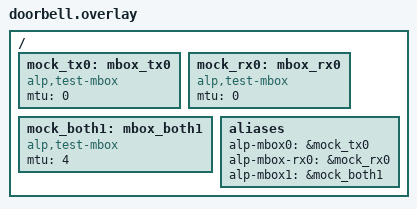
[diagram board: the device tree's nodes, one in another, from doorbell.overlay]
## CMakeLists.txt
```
# SPDX-License-Identifier: Apache-2.0

cmake_minimum_required(VERSION 3.20)

find_package(Zephyr REQUIRED HINTS $ENV{ZEPHYR_BASE})
project(alp_sdk_mproc_test LANGUAGES C)

target_sources(app PRIVATE src/main.c)

# alp_sdk.mproc.doorbell: mock MBOX controllers (src/mbox_mock.c).
if(ALP_MPROC_TEST_DOORBELL)
  target_sources(app PRIVATE src/mbox_mock.c)
  target_compile_definitions(app PRIVATE ALP_MPROC_TEST_DOORBELL)
endif()
```

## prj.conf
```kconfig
# SPDX-License-Identifier: Apache-2.0

CONFIG_ZTEST=y
CONFIG_ALP_SDK=y
CONFIG_LOG=y
CONFIG_PRINTK=y
CONFIG_THREAD_LOCAL_STORAGE=y
CONFIG_MAIN_STACK_SIZE=4096
```

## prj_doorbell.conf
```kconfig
# SPDX-License-Identifier: Apache-2.0
CONFIG_MBOX=y
CONFIG_ALP_SDK_MPROC=y
```

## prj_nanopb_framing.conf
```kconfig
# SPDX-License-Identifier: Apache-2.0
# Twister overlay: flips on CONFIG_ALP_SDK_MPROC_NANOPB_FRAMING so the
# alp_mbox_send / mbox_rx_cb framing code path in mproc_zephyr.c is
# compile-verified.  Real mbox roundtrip remains parked behind HIL
# (no mbox device exists under native_sim); the same encode/decode
# ZTESTs in src/main.c cover the framing helper directly.

CONFIG_MBOX=y
CONFIG_ALP_SDK_MPROC=y
CONFIG_ALP_SDK_MPROC_NANOPB_FRAMING=y
CONFIG_ALP_SDK_MPROC_FRAME_MAX_BYTES=256
```

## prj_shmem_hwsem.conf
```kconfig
# SPDX-License-Identifier: Apache-2.0
#
# Extra config for the alp_sdk.mproc.shmem_hwsem scenario: turn the
# real MPROC backend on so alp_shmem_* + alp_hwsem_* dispatch
# through the DT-alias-lookup + k_sem paths (rather than the
# NOSUPPORT shortcircuit).
#
# CONFIG_MBOX=y is required because CONFIG_ALP_SDK_MPROC has
# `depends on MBOX` in zephyr/Kconfig -- without it the Kconfig
# solver silently demotes the assignment to 'n' and the wrapper
# keeps shortcircuiting to ALP_ERR_NOSUPPORT.

CONFIG_MBOX=y
CONFIG_ALP_SDK_MPROC=y
```

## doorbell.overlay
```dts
/*
 * SPDX-License-Identifier: Apache-2.0
 *
 * alp_sdk.mproc.doorbell: mock mbox pairs (alp-shmem0 comes from
 * native_sim_native_64.overlay; src/mbox_mock.c maps its 0x70000000).
 *   channel 0: tx mtu 0 (doorbell-only) + separate rx device (alp-mbox-rx0)
 *   channel 1: one device, mtu 4, no alp-mbox-rx1 (RX falls back to TX)
 */
/ {
	mock_tx0: mbox_tx0 {
		compatible = "alp,test-mbox";
		#mbox-cells = <1>;
		mtu = <0>;
		status = "okay";
	};
	mock_rx0: mbox_rx0 {
		compatible = "alp,test-mbox";
		#mbox-cells = <1>;
		mtu = <0>;
		status = "okay";
	};
	mock_both1: mbox_both1 {
		compatible = "alp,test-mbox";
		#mbox-cells = <1>;
		mtu = <4>;
		status = "okay";
	};

	aliases {
		alp-mbox0    = &mock_tx0;
		alp-mbox-rx0 = &mock_rx0;
		alp-mbox1    = &mock_both1;
	};
};
```

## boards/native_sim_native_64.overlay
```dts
/*
 * Copyright 2026 Alp Lab AB
 * SPDX-License-Identifier: Apache-2.0
 *
 * DT overlay for the alp_sdk.mproc.shmem_hwsem ZTEST scenario.
 * Declares two alp-shmem aliases backed by mmio-sram nodes with
 * arbitrary "addresses" -- native_sim never dereferences them; the
 * tests only verify the wrapper reports the DT-anchored base+size
 * verbatim.  Real-silicon boards define the same aliases against
 * actual reserved-memory carve-outs (orchestrator-allocated).
 */

/ {
    alp_shmem0_node: shmem@70000000 {
        compatible = "mmio-sram";
        reg = <0x70000000 0x1000>;
        status = "okay";
    };

    alp_shmem1_node: shmem@70001000 {
        compatible = "mmio-sram";
        reg = <0x70001000 0x800>;
        status = "okay";
    };

    aliases {
        alp-shmem0 = &alp_shmem0_node;
        alp-shmem1 = &alp_shmem1_node;
    };
};
```

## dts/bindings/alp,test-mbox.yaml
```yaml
# SPDX-License-Identifier: Apache-2.0
description: Test-only mbox mock for tests/zephyr/mproc (src/mbox_mock.c).
compatible: "alp,test-mbox"
include: [base.yaml, mailbox-controller.yaml]
properties:
  mtu:
    type: int
    default: 0
    description: Value mbox_mtu_get() reports; 0 mimics a doorbell-only controller.
```

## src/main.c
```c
/*
 * Copyright 2026 Alp Lab AB
 * SPDX-License-Identifier: Apache-2.0
 *
 * Smoke tests for <alp/mproc.h> under native_sim, covering four
 * buckets driven by the testcase.yaml scenarios:
 *
 *   1. NOSUPPORT-fallback (default scenario, CONFIG_ALP_SDK_MPROC=n).
 *      Guarded with #if !defined(CONFIG_ALP_SDK_MPROC).  Verifies
 *      alp_shmem_open / alp_mbox_open / alp_hwsem_open all return
 *      NULL with ALP_ERR_NOSUPPORT plus every NULL-arg branch
 *      stays safe.
 *
 *   2. shmem-impl (alp_sdk.mproc.shmem_hwsem scenario,
 *      CONFIG_ALP_SDK_MPROC=y + boards/native_sim_native_64.overlay
 *      declaring alp-shmem0 + alp-shmem1).  Guarded with
 *      #if defined(CONFIG_ALP_SDK_MPROC) && DT_NODE_HAS_STATUS(DT_ALIAS(alp_shmem0), okay).
 *      Verifies the DT-alias lookup table resolves names to the
 *      right base+size, unknown names hit NOT_READY, the handle
 *      pool exhausts cleanly.
 *
 *   3. hwsem-impl (same scenario as shmem-impl).  Verifies the
 *      k_sem-backed lock/unlock cycle, contention between distinct
 *      handles on the same id, timed lock semantics, out-of-range
 *      id rejection, and the "unlock without lock returns INVAL"
 *      contract.
 *
 *   4. IPC envelope framing (always on -- no MPROC backend needed).
 *      Exercises alp_mproc_frame_encode / alp_mproc_frame_decode
 *      directly so the interim placeholder codec stays correct
 *      ahead of the (deferred, no committed version) nanopb-generated
 *      wire format.  The
 *      alp_sdk.mproc.nanopb_framing scenario additionally compiles
 *      CONFIG_ALP_SDK_MPROC_NANOPB_FRAMING=y so the framing branch
 *      in alp_mbox_send / mbox_rx_cb builds cleanly.
 */

#include <string.h>

#include <zephyr/devicetree.h>
#include <zephyr/ztest.h>

#include "alp/peripheral.h"
#include "alp/mproc.h"
#include "proto/alp_mproc_frame.h"

ZTEST_SUITE(alp_mproc, NULL, NULL, NULL, NULL, NULL);

/* The "no backend" assertions below presume CONFIG_ALP_SDK_MPROC=n
 * so the wrapper shortcircuits to NOSUPPORT.  When MPROC is on (used
 * by the framing scenario below) the wrapper validates args and
 * walks the DT-alias lookup, which yields NOT_READY under native_sim
 * because no `alp-mbox0` / `alp_shmem0` aliases exist there.  Both
 * states are "no backend" -- the framing scenario covers the
 * framing path itself, not these no-backend assertions, so skipping
 * them under MPROC=y keeps each scenario laser-focused. */
#if !defined(CONFIG_ALP_SDK_MPROC)

ZTEST(alp_mproc, test_shmem_open_no_backend_returns_null)
{
	alp_shmem_config_t cfg = { .name = "alp_shmem0", .size = 4096 };
	alp_shmem_t       *s   = alp_shmem_open(&cfg);
	zassert_is_null(s);
	zassert_equal(alp_last_error(), ALP_ERR_NOSUPPORT);
}

ZTEST(alp_mproc, test_shmem_open_null_invalid)
{
	zassert_is_null(alp_shmem_open(NULL));
	zassert_equal(alp_last_error(), ALP_ERR_INVAL);
}

ZTEST(alp_mproc, test_shmem_view_null_handle_errors)
{
	void  *base = (void *)0xDEADBEEF;
	size_t size = 999;
	zassert_equal(alp_shmem_view(NULL, &base, &size), ALP_ERR_NOT_READY);
	zassert_is_null(base);
	zassert_equal(size, 0);
	alp_shmem_close(NULL);
}

#ifndef ALP_MPROC_TEST_DOORBELL /* the doorbell scenario defines alp-mbox0 */
ZTEST(alp_mproc, test_mbox_open_no_backend_returns_null)
{
	alp_mbox_config_t cfg = { .channel = 0, .peer = ALP_CORE_M55_HE };
	alp_mbox_t       *m   = alp_mbox_open(&cfg);
	zassert_is_null(m);
	zassert_equal(alp_last_error(), ALP_ERR_NOSUPPORT);
}
#endif

ZTEST(alp_mproc, test_mbox_lifecycle_null_handle_safe)
{
	uint8_t buf[4] = { 0 };
	zassert_equal(alp_mbox_send(NULL, buf, sizeof(buf), 100), ALP_ERR_NOT_READY);
	zassert_equal(alp_mbox_set_callback(NULL, NULL, NULL), ALP_ERR_NOT_READY);
	alp_mbox_close(NULL);
}

ZTEST(alp_mproc, test_hwsem_open_no_backend_returns_null)
{
	alp_hwsem_t *s = alp_hwsem_open(0);
	zassert_is_null(s);
	zassert_equal(alp_last_error(), ALP_ERR_NOSUPPORT);
}

ZTEST(alp_mproc, test_hwsem_lifecycle_null_handle_safe)
{
	zassert_equal(alp_hwsem_try_lock(NULL), ALP_ERR_NOT_READY);
	zassert_equal(alp_hwsem_lock(NULL, 100), ALP_ERR_NOT_READY);
	zassert_equal(alp_hwsem_unlock(NULL), ALP_ERR_NOT_READY);
	alp_hwsem_close(NULL);
}

#endif /* !CONFIG_ALP_SDK_MPROC */

/* ------------------------------------------------------------------ */
/* IPC envelope (src/common/proto/alp_mproc_frame.{h,c}) — interim,   */
/* deferred (no committed version for the real nanopb wire)           */
/*                                                                     */
/* Placeholder binary framing exercised here directly because no real  */
/* mbox peer is available under native_sim.  When the eventual         */
/* nanopb codec drops in, these tests get rewritten against the        */
/* generated pb_encode / pb_decode entry points and verify the same    */
/* round-trip contract.                                                */
/* ------------------------------------------------------------------ */

ZTEST(alp_mproc, test_frame_encode_decode_roundtrip)
{
	const uint8_t payload[] = { 0xDE, 0xAD, 0xBE, 0xEF };
	uint8_t       framed[64];
	size_t        framed_len = 0;
	zassert_equal(
	    alp_mproc_frame_encode(42, payload, sizeof(payload), framed, sizeof(framed), &framed_len),
	    ALP_OK);
	zassert_equal(framed_len, ALP_MPROC_FRAME_HEADER_BYTES + sizeof(payload));

	uint32_t       seq         = 0;
	const uint8_t *payload_out = NULL;
	size_t         payload_len = 0;
	zassert_equal(alp_mproc_frame_decode(framed, framed_len, &seq, &payload_out, &payload_len),
	              ALP_OK);
	zassert_equal(seq, 42u);
	zassert_equal(payload_len, sizeof(payload));
	zassert_not_null(payload_out);
	zassert_equal(memcmp(payload_out, payload, sizeof(payload)),
	              0,
	              "payload bytes must round-trip unchanged");
}

ZTEST(alp_mproc, test_frame_encode_zero_payload_succeeds)
{
	uint8_t framed[ALP_MPROC_FRAME_HEADER_BYTES];
	size_t  framed_len = 0;
	zassert_equal(alp_mproc_frame_encode(1, NULL, 0, framed, sizeof(framed), &framed_len), ALP_OK);
	zassert_equal(framed_len, ALP_MPROC_FRAME_HEADER_BYTES);
}

ZTEST(alp_mproc, test_frame_encode_null_out_invalid)
{
	size_t framed_len = 99;
	zassert_equal(alp_mproc_frame_encode(1, "abc", 3, NULL, 999, &framed_len), ALP_ERR_INVAL);
	zassert_equal(framed_len, 0u, "out_len must be zeroed on failure");
}

ZTEST(alp_mproc, test_frame_encode_payload_null_with_nonzero_len)
{
	uint8_t framed[32];
	zassert_equal(alp_mproc_frame_encode(1, NULL, 4, framed, sizeof(framed), NULL), ALP_ERR_INVAL);
}

ZTEST(alp_mproc, test_frame_encode_capacity_short)
{
	const uint8_t payload[] = { 1, 2, 3, 4, 5, 6, 7, 8 };
	uint8_t       framed[ALP_MPROC_FRAME_HEADER_BYTES + 4]; /* too small for the 8-byte payload */
	zassert_equal(alp_mproc_frame_encode(1, payload, sizeof(payload), framed, sizeof(framed), NULL),
	              ALP_ERR_NOMEM);
}

ZTEST(alp_mproc, test_frame_decode_short_frame_errors)
{
	uint8_t frame[ALP_MPROC_FRAME_HEADER_BYTES - 1] = { 0 };
	zassert_equal(alp_mproc_frame_decode(frame, sizeof(frame), NULL, NULL, NULL), ALP_ERR_IO);
}

ZTEST(alp_mproc, test_frame_decode_bad_magic_errors)
{
	/* Encode a valid frame, then corrupt the magic. */
	const uint8_t payload[] = { 0xAB };
	uint8_t       framed[32];
	size_t        framed_len = 0;
	zassert_equal(
	    alp_mproc_frame_encode(1, payload, sizeof(payload), framed, sizeof(framed), &framed_len),
	    ALP_OK);
	framed[0] ^= 0xFFu;
	zassert_equal(alp_mproc_frame_decode(framed, framed_len, NULL, NULL, NULL), ALP_ERR_IO);
}

ZTEST(alp_mproc, test_frame_decode_declared_len_overflow_errors)
{
	/* Header claims a payload longer than the frame -- a peer-side
     * bug or a truncated transfer.  Receiver must drop. */
	uint8_t framed[ALP_MPROC_FRAME_HEADER_BYTES + 4];
	/* Magic */
	framed[0] = 0x41;
	framed[1] = 0x4D;
	framed[2] = 0x50;
	framed[3] = 0x46;
	/* Sequence */
	framed[4] = 1;
	framed[5] = 0;
	framed[6] = 0;
	framed[7] = 0;
	/* Declared length = 100, actual payload only 4 bytes */
	framed[8]  = 100;
	framed[9]  = 0;
	framed[10] = 0;
	framed[11] = 0;
	framed[12] = 0xDE;
	framed[13] = 0xAD;
	framed[14] = 0xBE;
	framed[15] = 0xEF;
	zassert_equal(alp_mproc_frame_decode(framed, sizeof(framed), NULL, NULL, NULL), ALP_ERR_IO);
}

ZTEST(alp_mproc, test_frame_decode_null_frame_invalid)
{
	uint32_t       seq         = 99;
	const uint8_t *payload_out = (const uint8_t *)0xDEADBEEF;
	size_t         payload_len = 99;
	zassert_equal(alp_mproc_frame_decode(NULL, 0, &seq, &payload_out, &payload_len), ALP_ERR_INVAL);
	zassert_equal(seq, 0u, "seq must be zeroed on failure");
	zassert_is_null(payload_out, "payload_out must be NULLed on failure");
	zassert_equal(payload_len, 0u, "payload_len must be zeroed on failure");
}

/* ------------------------------------------------------------------ */
/* Real backend (CONFIG_ALP_SDK_MPROC=y + DT overlay supplying        */
/* alp-shmem0..1 + the k_sem-backed hwsem fallback).                  */
/* ------------------------------------------------------------------ */
#if defined(CONFIG_ALP_SDK_MPROC) && DT_NODE_HAS_STATUS(DT_ALIAS(alp_shmem0), okay)

ZTEST(alp_mproc, test_shmem_open_resolves_name)
{
	alp_shmem_config_t cfg = { .name = "alp_shmem0", .size = 0 };
	alp_shmem_t       *s   = alp_shmem_open(&cfg);
	zassert_not_null(s, "open should resolve alp_shmem0 alias");

	void  *base = NULL;
	size_t size = 0;
	zassert_equal(alp_shmem_view(s, &base, &size), ALP_OK);
	zassert_equal((uintptr_t)base,
	              (uintptr_t)DT_REG_ADDR(DT_ALIAS(alp_shmem0)),
	              "base must match DT reg-address");
	zassert_equal(size, DT_REG_SIZE(DT_ALIAS(alp_shmem0)), "size must match DT reg-size");

	alp_shmem_close(s);
}

ZTEST(alp_mproc, test_shmem_open_unknown_name_returns_null)
{
	alp_shmem_config_t cfg = { .name = "nope_not_a_region", .size = 0 };
	zassert_is_null(alp_shmem_open(&cfg));
	zassert_equal(alp_last_error(), ALP_ERR_NOT_READY);
}

ZTEST(alp_mproc, test_shmem_open_two_regions)
{
	alp_shmem_config_t cfg0 = { .name = "alp_shmem0", .size = 0 };
	alp_shmem_config_t cfg1 = { .name = "alp_shmem1", .size = 0 };
	alp_shmem_t       *s0   = alp_shmem_open(&cfg0);
	alp_shmem_t       *s1   = alp_shmem_open(&cfg1);
	zassert_not_null(s0);
	zassert_not_null(s1);
	zassert_not_equal((void *)s0, (void *)s1, "distinct handles for distinct regions");

	void  *base0 = NULL, *base1 = NULL;
	size_t size0 = 0, size1 = 0;
	zassert_equal(alp_shmem_view(s0, &base0, &size0), ALP_OK);
	zassert_equal(alp_shmem_view(s1, &base1, &size1), ALP_OK);
	zassert_not_equal((uintptr_t)base0, (uintptr_t)base1);

	alp_shmem_close(s0);
	alp_shmem_close(s1);
}

ZTEST(alp_mproc, test_shmem_open_exhausts_pool)
{
	/* This test specifically exercises the NOMEM path on the 3rd open.
     * If the pool grows, open the right number to exhaust it instead.
     */
	BUILD_ASSERT(CONFIG_ALP_SDK_MAX_SHMEM_HANDLES == 2,
	             "test assumes default pool of 2; revisit if Kconfig default changes");

	/* CONFIG_ALP_SDK_MAX_SHMEM_HANDLES = 2 by default; open both then
     * verify a third open with the same name fails with NOMEM. */
	alp_shmem_config_t cfg = { .name = "alp_shmem0", .size = 0 };
	alp_shmem_t       *a   = alp_shmem_open(&cfg);
	alp_shmem_t       *b   = alp_shmem_open(&cfg);
	zassert_not_null(a);
	zassert_not_null(b);
	zassert_is_null(alp_shmem_open(&cfg));
	zassert_equal(alp_last_error(), ALP_ERR_NOMEM);
	alp_shmem_close(a);
	alp_shmem_close(b);
}

ZTEST(alp_mproc, test_hwsem_lock_unlock_cycle)
{
	alp_hwsem_t *sem = alp_hwsem_open(0);
	zassert_not_null(sem);

	zassert_equal(alp_hwsem_try_lock(sem), ALP_OK);
	/* Holding -- the k_sem behind id 0 is now count=0.  A second
     * try_lock from this same handle would return ALP_ERR_BUSY
     * (binary-mutex semantics, limit=1).  We don't exercise that
     * here; the distinct-handles-same-id test covers contention. */

	zassert_equal(alp_hwsem_unlock(sem), ALP_OK);
	alp_hwsem_close(sem);
}

ZTEST(alp_mproc, test_hwsem_distinct_handles_same_id_contend)
{
	alp_hwsem_t *a = alp_hwsem_open(1);
	alp_hwsem_t *b = alp_hwsem_open(1);
	zassert_not_null(a);
	zassert_not_null(b);

	zassert_equal(alp_hwsem_try_lock(a), ALP_OK);
	/* Different handle, same hwsem_id -> second try_lock must fail. */
	zassert_equal(alp_hwsem_try_lock(b), ALP_ERR_BUSY);
	zassert_equal(alp_hwsem_unlock(a), ALP_OK);
	/* After release the second handle can take it. */
	zassert_equal(alp_hwsem_try_lock(b), ALP_OK);
	zassert_equal(alp_hwsem_unlock(b), ALP_OK);

	alp_hwsem_close(a);
	alp_hwsem_close(b);
}

ZTEST(alp_mproc, test_hwsem_lock_with_timeout_times_out)
{
	alp_hwsem_t *a = alp_hwsem_open(2);
	alp_hwsem_t *b = alp_hwsem_open(2);
	zassert_equal(alp_hwsem_try_lock(a), ALP_OK);
	/* Blocking lock on the same id must time out within ~50 ms. */
	zassert_equal(alp_hwsem_lock(b, 50), ALP_ERR_TIMEOUT);
	zassert_equal(alp_hwsem_unlock(a), ALP_OK);
	alp_hwsem_close(a);
	alp_hwsem_close(b);
}

ZTEST(alp_mproc, test_hwsem_open_out_of_range)
{
	/* The fallback supports hwsem_id < 16. */
	zassert_is_null(alp_hwsem_open(99));
	zassert_equal(alp_last_error(), ALP_ERR_OUT_OF_RANGE);
}

ZTEST(alp_mproc, test_hwsem_unlock_without_lock_returns_inval)
{
	alp_hwsem_t *sem = alp_hwsem_open(3);
	zassert_not_null(sem);
	/* Not held -- unlock must reject so a buggy app doesn't release
     * a hwsem it never took. */
	zassert_equal(alp_hwsem_unlock(sem), ALP_ERR_INVAL);
	alp_hwsem_close(sem);
}

#endif /* CONFIG_ALP_SDK_MPROC && DT_NODE_HAS_STATUS(DT_ALIAS(alp_shmem0), okay) */
```

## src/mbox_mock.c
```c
/*
 * Copyright 2026 Alp Lab AB
 * SPDX-License-Identifier: Apache-2.0
 *
 * Mock MBOX controllers + doorbell-slot tests for the Zephyr mproc backend
 * (alp_sdk.mproc.doorbell).  Covers the payload-less (mtu 0) doorbell path,
 * the oversize refusal for mtu > 0, and the alp-mbox-rxN receive alias with
 * its same-device fallback.  The alp-shmem0 node in native_sim_native_64.overlay
 * is the fixed address 0x70000000, which nothing maps on native_sim, so the
 * suite maps one anonymous page there itself (raw Linux x86-64 mmap syscall:
 * the app has no host libc) and skips where that is unavailable.
 */

#include <string.h>
#include <zephyr/device.h>
#include <zephyr/drivers/mbox.h>
#include <zephyr/ztest.h>

#include <alp/mproc.h>

#define DT_DRV_COMPAT alp_test_mbox

struct mock_data {
	mbox_callback_t cb;
	void           *cb_ctx;
	bool            enabled;
	int             sends;
	bool            last_null;
	size_t          last_size;
};

#define SHM_ADDR 0x70000000UL
#define SHM_SIZE 4096u
static uint8_t *g_shm;

static bool map_shm(void)
{
#if defined(__x86_64__) && defined(__linux__)
	/* mmap(SHM_ADDR, SHM_SIZE, PROT_READ|PROT_WRITE,
	 *      MAP_PRIVATE|MAP_ANONYMOUS|MAP_FIXED_NOREPLACE, -1, 0) */
	long          ret;
	register long r10 __asm__("r10") = 0x2 | 0x20 | 0x100000;
	register long r8 __asm__("r8")   = -1;
	register long r9 __asm__("r9")   = 0;
	__asm__ volatile(
	    "syscall"
	    : "=a"(ret)
	    : "0"(9L), "D"(SHM_ADDR), "S"((long)SHM_SIZE), "d"(3L), "r"(r10), "r"(r8), "r"(r9)
	    : "rcx", "r11", "memory");
	if (ret != (long)SHM_ADDR) return false;
	g_shm = (uint8_t *)SHM_ADDR;
	return true;
#else
	return false;
#endif
}

static void *suite_setup(void)
{
	if (!map_shm()) ztest_test_skip();
	return NULL;
}

static int mock_send(const struct device *dev, mbox_channel_id_t ch, const struct mbox_msg *msg)
{
	struct mock_data *d = dev->data;
	d->sends++;
	d->last_null = (msg == NULL);
	d->last_size = msg ? msg->size : 0;
	return 0;
}

static int
mock_register(const struct device *dev, mbox_channel_id_t ch, mbox_callback_t cb, void *ctx)
{
	struct mock_data *d = dev->data;
	d->cb               = cb;
	d->cb_ctx           = ctx;
	return 0;
}

static int mock_mtu(const struct device *dev)
{
	return ((const int *)dev->config)[0];
}

static uint32_t mock_max_ch(const struct device *dev)
{
	return 32;
}

static int mock_set_enabled(const struct device *dev, mbox_channel_id_t ch, bool en)
{
	((struct mock_data *)dev->data)->enabled = en;
	return 0;
}

static const struct mbox_driver_api mock_api = {
	.send              = mock_send,
	.register_callback = mock_register,
	.mtu_get           = mock_mtu,
	.max_channels_get  = mock_max_ch,
	.set_enabled       = mock_set_enabled,
};

#define MOCK_INST(n) \
	static struct mock_data mock_data_##n; \
	static const int        mock_cfg_##n = DT_INST_PROP(n, mtu); \
	DEVICE_DT_INST_DEFINE(n, NULL, NULL, &mock_data_##n, &mock_cfg_##n, POST_KERNEL, 0, &mock_api);
DT_INST_FOREACH_STATUS_OKAY(MOCK_INST)

#define MOCK(label) ((struct mock_data *)DEVICE_DT_GET(DT_NODELABEL(label))->data)

static int     g_rx_count;
static size_t  g_rx_len;
static uint8_t g_rx_bytes[64];

static void on_msg(uint32_t channel, const void *data, size_t len, void *user)
{
	g_rx_count++;
	g_rx_len = len;
	memcpy(g_rx_bytes, data, len < sizeof(g_rx_bytes) ? len : sizeof(g_rx_bytes));
}

ZTEST_SUITE(alp_mproc_doorbell, NULL, suite_setup, NULL, NULL, NULL);

ZTEST(alp_mproc_doorbell, test_doorbell_only_carries_payload_in_shmem_slot)
{
	alp_mbox_config_t cfg = { .channel = 0, .peer = ALP_CORE_M55_HE };
	alp_mbox_t       *mb  = alp_mbox_open(&cfg);
	zassert_not_null(mb, "mtu 0 + alp-shmem0 present must open");

	const uint8_t msg[8]  = { 1, 2, 3, 4, 5, 6, 7, 8 };
	MOCK(mock_tx0)->sends = 0;
	zassert_equal(alp_mbox_send(mb, msg, sizeof(msg), 10), ALP_OK);
	zassert_equal(MOCK(mock_tx0)->sends, 1);
	zassert_true(MOCK(mock_tx0)->last_null, "doorbell-only send must pass a NULL message");
	/* slot = last 64 bytes of the 4 KiB region: u32 len, then data */
	zassert_equal(*(volatile uint32_t *)&g_shm[SHM_SIZE - 64], 8u);
	zassert_mem_equal(&g_shm[SHM_SIZE - 60], msg, sizeof(msg));

	uint8_t big[61] = { 0 };
	zassert_equal(alp_mbox_send(mb, big, sizeof(big), 10), ALP_ERR_OUT_OF_RANGE);
	zassert_equal(MOCK(mock_tx0)->sends, 1, "oversize must not ring the doorbell");

	/* RX: callback goes on the rx device; a NULL-message ring reads the slot. */
	g_rx_count = 0;
	zassert_equal(alp_mbox_set_callback(mb, on_msg, NULL), ALP_OK);
	zassert_true(MOCK(mock_rx0)->enabled, "rx alias must be the enabled device");
	zassert_false(MOCK(mock_tx0)->enabled, "tx device must not be touched for RX");
	MOCK(mock_rx0)->cb(DEVICE_DT_GET(DT_NODELABEL(mock_rx0)), 0, MOCK(mock_rx0)->cb_ctx, NULL);
	zassert_equal(g_rx_count, 1);
	zassert_equal(g_rx_len, sizeof(msg));
	zassert_mem_equal(g_rx_bytes, msg, sizeof(msg));

	alp_mbox_close(mb);
}

ZTEST(alp_mproc_doorbell, test_payload_mbox_refuses_over_mtu_and_rx_falls_back)
{
	alp_mbox_config_t cfg = { .channel = 1, .peer = ALP_CORE_M55_HE };
	alp_mbox_t       *mb  = alp_mbox_open(&cfg);
	zassert_not_null(mb);

	const uint8_t msg[5] = { 1, 2, 3, 4, 5 };
	zassert_equal(alp_mbox_send(mb, msg, 5, 10), ALP_ERR_OUT_OF_RANGE, "5 > mtu 4");
	zassert_equal(MOCK(mock_both1)->sends, 0);
	zassert_equal(alp_mbox_send(mb, msg, 4, 10), ALP_OK);
	zassert_false(MOCK(mock_both1)->last_null, "mtu > 0 keeps the in-message payload path");
	zassert_equal(MOCK(mock_both1)->last_size, 4u);

	/* no alp-mbox-rx1: callback lands on the same device */
	zassert_equal(alp_mbox_set_callback(mb, on_msg, NULL), ALP_OK);
	zassert_true(MOCK(mock_both1)->enabled);
	alp_mbox_close(mb);
}
```
